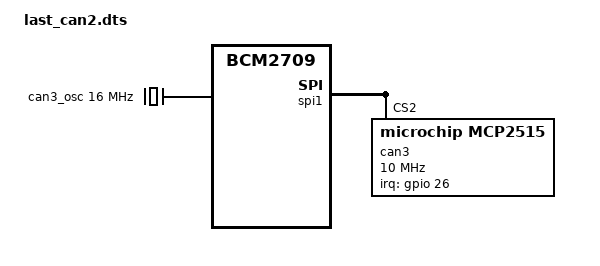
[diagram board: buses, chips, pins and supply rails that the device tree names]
/* * Device tree overlay for mcp251x/can0 on spi0.0 */
/dts-v1/;
/plugin/;
/ {
   compatible = "brcm,bcm2835", "brcm,bcm2836", "brcm,bcm2708", "brcm,bcm2709";
   /* disable spi-dev for spi1.2 */
   fragment@0 {
       target = <&spi1>;
       __overlay__ {
           status = "okay";
       };
   };
   fragment@1 {
   target = <&spidev2>;
   __overlay__ {
       status = "disabled";
   };
   };
   /* the interrupt pin of the can-controller */
   fragment@2 {
       target = <&gpio>;
       __overlay__ {
           can3_pins: can3_pins {
               brcm,pins = <26>;
               brcm,function = <0>; /* input */
           };
       };
   };
   /* the clock/oscillator of the can-controller */
   fragment@3 {
       target-path = "/clocks";
       __overlay__ {
           /* external oscillator of mcp2515 on SPI1.2 */
           can3_osc: can3_osc {
               compatible = "fixed-clock";
               #clock-cells = <0>;
               clock-frequency  = <16000000>;
           };
       };
   };
   /* the spi config of the can-controller itself binding everything together */
   fragment@4 {
       target = <&spi1>;
       __overlay__ {
           /* needed to avoid dtc warning */
           #address-cells = <1>;
           #size-cells = <0>;
           can3: mcp2515@1 {
               reg = <2>;
               compatible = "microchip,mcp2515";
               pinctrl-names = "default";
               pinctrl-0 = <&can3_pins>;
               spi-max-frequency = <10000000>;
               interrupt-parent = <&gpio>;
               interrupts = <26 0x2>;
               clocks = <&can3_osc>;
           };
       };
   };
   __overrides__ {
       oscillator = <&can3_osc>,"clock-frequency:0";
       spimaxfrequency = <&can3>,"spi-max-frequency:0";
       interrupt = <&can3_pins>,"brcm,pins:0",<&can3>,"interrupts:0";
   };
};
